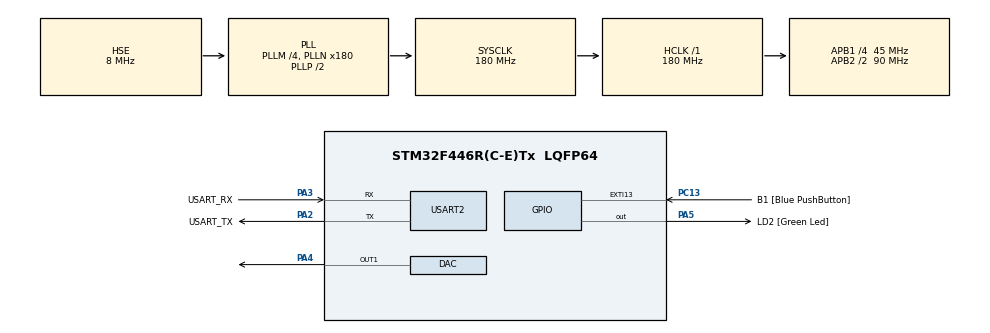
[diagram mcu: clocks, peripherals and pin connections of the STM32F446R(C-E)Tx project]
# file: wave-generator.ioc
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DAC.DAC_Trigger=DAC_TRIGGER_T2_TRGO
Dma.DAC1.0.Direction=DMA_MEMORY_TO_PERIPH
Dma.DAC1.0.FIFOMode=DMA_FIFOMODE_DISABLE
Dma.DAC1.0.Instance=DMA1_Stream5
Dma.DAC1.0.MemDataAlignment=DMA_MDATAALIGN_WORD
Dma.DAC1.0.MemInc=DMA_MINC_ENABLE
Dma.DAC1.0.Mode=DMA_CIRCULAR
Dma.DAC1.0.PeriphDataAlignment=DMA_PDATAALIGN_WORD
Dma.DAC1.0.PeriphInc=DMA_PINC_DISABLE
Dma.DAC1.0.Priority=DMA_PRIORITY_LOW
Dma.Request0=DAC1
Mcu.Family=STM32F4
Mcu.Name=STM32F446R(C-E)Tx
Mcu.Package=LQFP64
NVIC.DMA1_Stream5_IRQn=true\:0\:0\:false\:false\:true\:false\:true
NVIC.PriorityGroup=NVIC_PRIORITYGROUP_0
NVIC.USART2_IRQn=true\:0\:0\:false\:false\:true\:true\:true
PA13.GPIO_Label=TMS
PA13.Mode=Serial_Wire
PA13.Signal=SYS_JTMS-SWDIO
PA14.GPIO_Label=TCK
PA14.Mode=Serial_Wire
PA14.Signal=SYS_JTCK-SWCLK
PA2.GPIO_Label=USART_TX
PA2.Mode=Asynchronous
PA2.Signal=USART2_TX
PA3.GPIO_Label=USART_RX
PA3.Mode=Asynchronous
PA3.Signal=USART2_RX
PA4.Signal=COMP_DAC1_group
PA5.GPIO_Label=LD2 [Green Led]
PA5.Signal=GPIO_Output
PB3.GPIO_Label=SWO
PB3.Signal=SYS_JTDO-SWO
PC13.GPIO_Label=B1 [Blue PushButton]
PC13.GPIO_ModeDefaultEXTI=GPIO_MODE_IT_FALLING
PC13.Signal=GPXTI13
PC14-OSC32_IN.Mode=LSE-External-Oscillator
PC14-OSC32_IN.Signal=RCC_OSC32_IN
PC15-OSC32_OUT.Mode=LSE-External-Oscillator
PC15-OSC32_OUT.Signal=RCC_OSC32_OUT
PH0-OSC_IN.Mode=HSE-External-Oscillator
PH0-OSC_IN.Signal=RCC_OSC_IN
PH1-OSC_OUT.Mode=HSE-External-Oscillator
PH1-OSC_OUT.Signal=RCC_OSC_OUT
ProjectManager.HeapSize=0x200
ProjectManager.StackSize=0x400
ProjectManager.TargetToolchain=STM32CubeIDE
RCC.48MHZClocksFreq_Value=84000000
RCC.AHBFreq_Value=180000000
RCC.APB1CLKDivider=RCC_HCLK_DIV4
RCC.APB1Freq_Value=45000000
RCC.APB1TimFreq_Value=90000000
RCC.APB2CLKDivider=RCC_HCLK_DIV2
RCC.APB2Freq_Value=90000000
RCC.APB2TimFreq_Value=180000000
RCC.CortexFreq_Value=180000000
RCC.FLatency-AdvancedSettings=FLASH_LATENCY_5
RCC.HCLKFreq_Value=180000000
RCC.HSE_VALUE=8000000
RCC.HSI_VALUE=16000000
RCC.PLLM=4
RCC.PLLN=180
RCC.PLLSourceVirtual=RCC_PLLSOURCE_HSE
RCC.SYSCLKFreq_VALUE=180000000
RCC.SYSCLKSource=RCC_SYSCLKSOURCE_PLLCLK
RCC.USBFreq_Value=180000000
RCC.VCOOutputFreq_Value=360000000
SH.COMP_DAC1_group.0=DAC_OUT1,DAC_OUT1
TIM2.Period=200
TIM2.Prescaler=9
TIM2.TIM_MasterOutputTrigger=TIM_TRGO_UPDATE
USART2.VirtualMode=VM_ASYNC
VP_TIM2_VS_ClockSourceINT.Mode=Internal
board=NUCLEO-F446RE

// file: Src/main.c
/* USER CODE BEGIN Header */
/**
  ******************************************************************************
  * @file           : main.c
  * @brief          : Main program body
  ******************************************************************************
  * @attention
  *
  * <h2><center>&copy; Copyright (c) 2020 STMicroelectronics.
  * All rights reserved.</center></h2>
  *
  * This software component is licensed by ST under BSD 3-Clause license,
  * the "License"; You may not use this file except in compliance with the
  * License. You may obtain a copy of the License at:
  *                        opensource.org/licenses/BSD-3-Clause
  *
  ******************************************************************************
  */
/* USER CODE END Header */

#include "main.h"

/* USER CODE BEGIN Includes */
#include "app_mng.h"
/* USER CODE END Includes */

DAC_HandleTypeDef hdac;
DMA_HandleTypeDef hdma_dac1;

TIM_HandleTypeDef htim2;

UART_HandleTypeDef huart2;

void SystemClock_Config(void);
static void MX_GPIO_Init(void);
static void MX_DMA_Init(void);
static void MX_USART2_UART_Init(void);
static void MX_DAC_Init(void);
static void MX_TIM2_Init(void);

int main(void)
{

  /* MCU Configuration--------------------------------------------------------*/

  /* Reset of all peripherals, Initializes the Flash interface and the Systick. */
  HAL_Init();

  /* Configure the system clock */
  SystemClock_Config();

  /* Initialize all configured peripherals */
  MX_GPIO_Init();
  MX_DMA_Init();
  MX_USART2_UART_Init();
  MX_DAC_Init();
  MX_TIM2_Init();
  /* USER CODE BEGIN 2 */

  APP_Init();
  /* USER CODE END 2 */

  /* Infinite loop */
  while (1)
  {

    /* USER CODE BEGIN 3 */
      (void) APP_Run(NULL);
  }
  /* USER CODE END 3 */
}

void SystemClock_Config(void)
{
  RCC_OscInitTypeDef RCC_OscInitStruct = {0};
  RCC_ClkInitTypeDef RCC_ClkInitStruct = {0};

  /** Configure the main internal regulator output voltage
  */
  __HAL_RCC_PWR_CLK_ENABLE();
  __HAL_PWR_VOLTAGESCALING_CONFIG(PWR_REGULATOR_VOLTAGE_SCALE1);
  /** Initializes the CPU, AHB and APB busses clocks
  */
  RCC_OscInitStruct.OscillatorType = RCC_OSCILLATORTYPE_HSE;
  RCC_OscInitStruct.HSEState = RCC_HSE_ON;
  RCC_OscInitStruct.PLL.PLLState = RCC_PLL_ON;
  RCC_OscInitStruct.PLL.PLLSource = RCC_PLLSOURCE_HSE;
  RCC_OscInitStruct.PLL.PLLM = 4;
  RCC_OscInitStruct.PLL.PLLN = 180;
  RCC_OscInitStruct.PLL.PLLP = RCC_PLLP_DIV2;
  RCC_OscInitStruct.PLL.PLLQ = 2;
  RCC_OscInitStruct.PLL.PLLR = 2;
  if (HAL_RCC_OscConfig(&RCC_OscInitStruct) != HAL_OK)
  {
    Error_Handler();
  }
  /** Activate the Over-Drive mode
  */
  if (HAL_PWREx_EnableOverDrive() != HAL_OK)
  {
    Error_Handler();
  }
  /** Initializes the CPU, AHB and APB busses clocks
  */
  RCC_ClkInitStruct.ClockType = RCC_CLOCKTYPE_HCLK|RCC_CLOCKTYPE_SYSCLK
                              |RCC_CLOCKTYPE_PCLK1|RCC_CLOCKTYPE_PCLK2;
  RCC_ClkInitStruct.SYSCLKSource = RCC_SYSCLKSOURCE_PLLCLK;
  RCC_ClkInitStruct.AHBCLKDivider = RCC_SYSCLK_DIV1;
  RCC_ClkInitStruct.APB1CLKDivider = RCC_HCLK_DIV4;
  RCC_ClkInitStruct.APB2CLKDivider = RCC_HCLK_DIV2;

  if (HAL_RCC_ClockConfig(&RCC_ClkInitStruct, FLASH_LATENCY_5) != HAL_OK)
  {
    Error_Handler();
  }
}

static void MX_DAC_Init(void)
{

  DAC_ChannelConfTypeDef sConfig = {0};

  /** DAC Initialization
  */
  hdac.Instance = DAC;
  if (HAL_DAC_Init(&hdac) != HAL_OK)
  {
    Error_Handler();
  }
  /** DAC channel OUT1 config
  */
  sConfig.DAC_Trigger = DAC_TRIGGER_T2_TRGO;
  sConfig.DAC_OutputBuffer = DAC_OUTPUTBUFFER_ENABLE;
  if (HAL_DAC_ConfigChannel(&hdac, &sConfig, DAC_CHANNEL_1) != HAL_OK)
  {
    Error_Handler();
  }

}

static void MX_TIM2_Init(void)
{

  TIM_ClockConfigTypeDef sClockSourceConfig = {0};
  TIM_MasterConfigTypeDef sMasterConfig = {0};

  htim2.Instance = TIM2;
  htim2.Init.Prescaler = 9;
  htim2.Init.CounterMode = TIM_COUNTERMODE_UP;
  htim2.Init.Period = 200;
  htim2.Init.ClockDivision = TIM_CLOCKDIVISION_DIV1;
  htim2.Init.AutoReloadPreload = TIM_AUTORELOAD_PRELOAD_DISABLE;
  if (HAL_TIM_Base_Init(&htim2) != HAL_OK)
  {
    Error_Handler();
  }
  sClockSourceConfig.ClockSource = TIM_CLOCKSOURCE_INTERNAL;
  if (HAL_TIM_ConfigClockSource(&htim2, &sClockSourceConfig) != HAL_OK)
  {
    Error_Handler();
  }
  sMasterConfig.MasterOutputTrigger = TIM_TRGO_UPDATE;
  sMasterConfig.MasterSlaveMode = TIM_MASTERSLAVEMODE_DISABLE;
  if (HAL_TIMEx_MasterConfigSynchronization(&htim2, &sMasterConfig) != HAL_OK)
  {
    Error_Handler();
  }

}

static void MX_USART2_UART_Init(void)
{

  huart2.Instance = USART2;
  huart2.Init.BaudRate = 115200;
  huart2.Init.WordLength = UART_WORDLENGTH_8B;
  huart2.Init.StopBits = UART_STOPBITS_1;
  huart2.Init.Parity = UART_PARITY_NONE;
  huart2.Init.Mode = UART_MODE_TX_RX;
  huart2.Init.HwFlowCtl = UART_HWCONTROL_NONE;
  huart2.Init.OverSampling = UART_OVERSAMPLING_16;
  if (HAL_UART_Init(&huart2) != HAL_OK)
  {
    Error_Handler();
  }

}

static void MX_DMA_Init(void)
{

  /* DMA controller clock enable */
  __HAL_RCC_DMA1_CLK_ENABLE();

  /* DMA interrupt init */
  /* DMA1_Stream5_IRQn interrupt configuration */
  HAL_NVIC_SetPriority(DMA1_Stream5_IRQn, 0, 0);
  HAL_NVIC_EnableIRQ(DMA1_Stream5_IRQn);

}

static void MX_GPIO_Init(void)
{
  GPIO_InitTypeDef GPIO_InitStruct = {0};

  /* GPIO Ports Clock Enable */
  __HAL_RCC_GPIOC_CLK_ENABLE();
  __HAL_RCC_GPIOH_CLK_ENABLE();
  __HAL_RCC_GPIOA_CLK_ENABLE();
  __HAL_RCC_GPIOB_CLK_ENABLE();

  /*Configure GPIO pin Output Level */
  HAL_GPIO_WritePin(LD2_GPIO_Port, LD2_Pin, GPIO_PIN_RESET);

  /*Configure GPIO pin : B1_Pin */
  GPIO_InitStruct.Pin = B1_Pin;
  GPIO_InitStruct.Mode = GPIO_MODE_IT_FALLING;
  GPIO_InitStruct.Pull = GPIO_NOPULL;
  HAL_GPIO_Init(B1_GPIO_Port, &GPIO_InitStruct);

  /*Configure GPIO pin : LD2_Pin */
  GPIO_InitStruct.Pin = LD2_Pin;
  GPIO_InitStruct.Mode = GPIO_MODE_OUTPUT_PP;
  GPIO_InitStruct.Pull = GPIO_NOPULL;
  GPIO_InitStruct.Speed = GPIO_SPEED_FREQ_LOW;
  HAL_GPIO_Init(LD2_GPIO_Port, &GPIO_InitStruct);

}

void Error_Handler(void)
{
}

/************************ (C) COPYRIGHT STMicroelectronics *****END OF FILE****/
